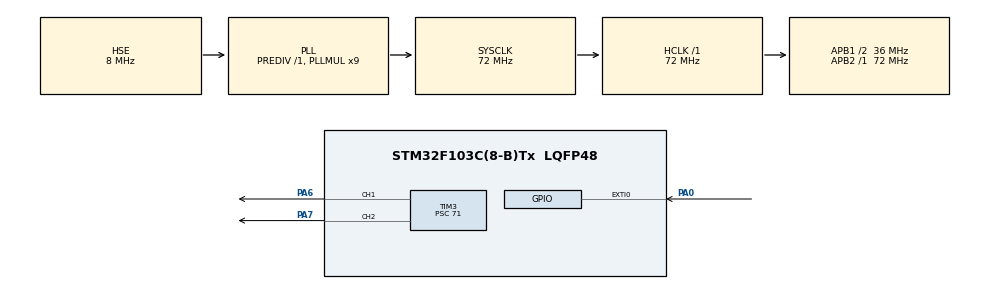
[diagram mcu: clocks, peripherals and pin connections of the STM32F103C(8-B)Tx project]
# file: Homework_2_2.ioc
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Mcu.Family=STM32F1
Mcu.Name=STM32F103C(8-B)Tx
Mcu.Package=LQFP48
NVIC.EXTI0_IRQn=true\:0\:0\:false\:false\:true\:true\:true\:true
NVIC.PriorityGroup=NVIC_PRIORITYGROUP_4
PA0-WKUP.GPIO_ModeDefaultEXTI=GPIO_MODE_IT_RISING_FALLING
PA0-WKUP.GPIO_PuPd=GPIO_PULLUP
PA0-WKUP.Signal=GPXTI0
PA13.Mode=Serial_Wire
PA13.Signal=SYS_JTMS-SWDIO
PA14.Mode=Serial_Wire
PA14.Signal=SYS_JTCK-SWCLK
PA6.Signal=S_TIM3_CH1
PA7.Signal=S_TIM3_CH2
PD0-OSC_IN.Mode=HSE-External-Oscillator
PD0-OSC_IN.Signal=RCC_OSC_IN
PD1-OSC_OUT.Mode=HSE-External-Oscillator
PD1-OSC_OUT.Signal=RCC_OSC_OUT
ProjectManager.HeapSize=0x200
ProjectManager.StackSize=0x400
ProjectManager.TargetToolchain=MDK-ARM V5.32
RCC.AHBFreq_Value=72000000
RCC.APB1CLKDivider=RCC_HCLK_DIV2
RCC.APB1Freq_Value=36000000
RCC.APB1TimFreq_Value=72000000
RCC.APB2Freq_Value=72000000
RCC.APB2TimFreq_Value=72000000
RCC.HCLKFreq_Value=72000000
RCC.PLLMUL=RCC_PLL_MUL9
RCC.PLLSourceVirtual=RCC_PLLSOURCE_HSE
RCC.SYSCLKFreq_VALUE=72000000
RCC.SYSCLKSource=RCC_SYSCLKSOURCE_PLLCLK
RCC.USBFreq_Value=72000000
SH.S_TIM3_CH1.0=TIM3_CH1,PWM Generation1 CH1
SH.S_TIM3_CH2.0=TIM3_CH2,PWM Generation2 CH2
TIM3.Channel-PWM\ Generation1\ CH1=TIM_CHANNEL_1
TIM3.Channel-PWM\ Generation2\ CH2=TIM_CHANNEL_2
TIM3.Period=19999
TIM3.Prescaler=71
board=custom

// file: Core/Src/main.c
/* USER CODE BEGIN Header */
/**
  ******************************************************************************
  * @file           : main.c
  * @brief          : Main program body
  ******************************************************************************
  * @attention
  *
  * Copyright (c) 2026 STMicroelectronics.
  * All rights reserved.
  *
  * This software is licensed under terms that can be found in the LICENSE file
  * in the root directory of this software component.
  * If no LICENSE file comes with this software, it is provided AS-IS.
  *
  ******************************************************************************
  */
/* USER CODE END Header */
#include "main.h"
#include "tim.h"
#include "gpio.h"

/* USER CODE BEGIN PV */
volatile uint8_t button =0;
/* USER CODE END PV */

void SystemClock_Config(void);

int main(void)
{

  /* MCU Configuration--------------------------------------------------------*/

  /* Reset of all peripherals, Initializes the Flash interface and the Systick. */
  HAL_Init();

  /* Configure the system clock */
  SystemClock_Config();

  /* Initialize all configured peripherals */
  MX_GPIO_Init();
  MX_TIM3_Init();
  /* USER CODE BEGIN 2 */
	HAL_TIM_PWM_Start(&htim3,TIM_CHANNEL_1);
	HAL_TIM_PWM_Start(&htim3,TIM_CHANNEL_2);

  /* USER CODE END 2 */

  /* Infinite loop */
  while (1)
  {

    /* USER CODE BEGIN 3 */
		if (button == 0) {
			__HAL_TIM_SET_COMPARE(&htim3,TIM_CHANNEL_2,0);
			for (int i = 0;i <= 19999;i+=100) {
				if (button != 0 ) {
					break;
				}
				__HAL_TIM_SET_COMPARE(&htim3,TIM_CHANNEL_1,i);
				HAL_Delay(5);
			}
			for (int i = 19999;i >= 0;i -= 100) {
				if (button != 0){
					break;
				}
				__HAL_TIM_SET_COMPARE(&htim3,TIM_CHANNEL_1,i);
				HAL_Delay(5);
			}
		}

		else {
			__HAL_TIM_SET_COMPARE(&htim3,TIM_CHANNEL_1,0);
		for (int spin = 0;spin <= 180;spin++){
			if (button != 1) {
			break;
			}
			uint16_t CCR = 500 + (spin * 2000/180);
			__HAL_TIM_SET_COMPARE(&htim3,TIM_CHANNEL_2,CCR);
			HAL_Delay(10);
			}
		for (int spin = 180;spin >=0;spin--){
			if (button != 1) {
			break;
			}
			uint16_t CCR = 500 + (spin * 2000/180);
			__HAL_TIM_SET_COMPARE(&htim3,TIM_CHANNEL_2,CCR);
			HAL_Delay(10);

		}
	}
}
  /* USER CODE END 3 */
}

void SystemClock_Config(void)
{
  RCC_OscInitTypeDef RCC_OscInitStruct = {0};
  RCC_ClkInitTypeDef RCC_ClkInitStruct = {0};

  /** Initializes the RCC Oscillators according to the specified parameters
  * in the RCC_OscInitTypeDef structure.
  */
  RCC_OscInitStruct.OscillatorType = RCC_OSCILLATORTYPE_HSE;
  RCC_OscInitStruct.HSEState = RCC_HSE_ON;
  RCC_OscInitStruct.HSEPredivValue = RCC_HSE_PREDIV_DIV1;
  RCC_OscInitStruct.HSIState = RCC_HSI_ON;
  RCC_OscInitStruct.PLL.PLLState = RCC_PLL_ON;
  RCC_OscInitStruct.PLL.PLLSource = RCC_PLLSOURCE_HSE;
  RCC_OscInitStruct.PLL.PLLMUL = RCC_PLL_MUL9;
  if (HAL_RCC_OscConfig(&RCC_OscInitStruct) != HAL_OK)
  {
    Error_Handler();
  }

  /** Initializes the CPU, AHB and APB buses clocks
  */
  RCC_ClkInitStruct.ClockType = RCC_CLOCKTYPE_HCLK|RCC_CLOCKTYPE_SYSCLK
                              |RCC_CLOCKTYPE_PCLK1|RCC_CLOCKTYPE_PCLK2;
  RCC_ClkInitStruct.SYSCLKSource = RCC_SYSCLKSOURCE_PLLCLK;
  RCC_ClkInitStruct.AHBCLKDivider = RCC_SYSCLK_DIV1;
  RCC_ClkInitStruct.APB1CLKDivider = RCC_HCLK_DIV2;
  RCC_ClkInitStruct.APB2CLKDivider = RCC_HCLK_DIV1;

  if (HAL_RCC_ClockConfig(&RCC_ClkInitStruct, FLASH_LATENCY_2) != HAL_OK)
  {
    Error_Handler();
  }
}

/* USER CODE BEGIN 4 */
void HAL_GPIO_EXTI_Callback(uint16_t GPIO_Pin) {
	if (GPIO_Pin == GPIO_PIN_0) {
		static uint32_t last = 0;
		uint32_t now = HAL_GetTick();
		if (now - last < 20) {
			return;
		}
		last = now;
		if (HAL_GPIO_ReadPin(GPIOA,GPIO_PIN_0) == GPIO_PIN_RESET) {
			if (button == 0) {
			button =1;
			}
			else {
			button =0;
			}
		}
	}

}

/* USER CODE END 4 */

void Error_Handler(void)
{
  __disable_irq();
  while (1)
  {
  }
}
